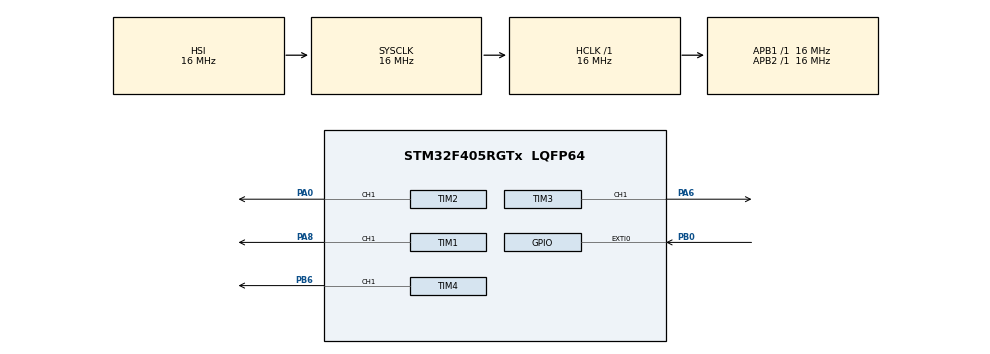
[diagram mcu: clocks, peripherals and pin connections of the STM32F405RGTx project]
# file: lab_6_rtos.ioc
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Mcu.Family=STM32F4
Mcu.Name=STM32F405RGTx
Mcu.Package=LQFP64
NVIC.EXTI0_IRQn=true\:0\:0\:false\:false\:true\:true\:true\:true
NVIC.PriorityGroup=NVIC_PRIORITYGROUP_4
PA0-WKUP.Signal=S_TIM2_CH1_ETR
PA6.Signal=S_TIM3_CH1
PA8.Signal=S_TIM1_CH1
PB0.GPIO_PuPd=GPIO_PULLDOWN
PB0.Signal=GPXTI0
PB6.Signal=S_TIM4_CH1
ProjectManager.HeapSize=0x200
ProjectManager.StackSize=0x400
ProjectManager.TargetToolchain=STM32CubeIDE
RCC.AHBFreq_Value=16000000
RCC.APB1Freq_Value=16000000
RCC.APB2Freq_Value=16000000
RCC.CortexFreq_Value=16000000
RCC.HSE_VALUE=25000000
RCC.HSI_VALUE=16000000
RCC.LSE_VALUE=32768
RCC.SYSCLKFreq_VALUE=16000000
RCC.VCOOutputFreq_Value=192000000
SH.S_TIM1_CH1.0=TIM1_CH1,PWM Generation1 CH1
SH.S_TIM2_CH1_ETR.0=TIM2_CH1,PWM Generation1 CH1
SH.S_TIM3_CH1.0=TIM3_CH1,PWM Generation1 CH1
SH.S_TIM4_CH1.0=TIM4_CH1,PWM Generation1 CH1
TIM1.Channel-PWM\ Generation1\ CH1=TIM_CHANNEL_1
TIM1.Period=41999
TIM1.Prescaler=1
TIM1.Pulse-PWM\ Generation1\ CH1=21000
TIM2.Channel-PWM\ Generation1\ CH1=TIM_CHANNEL_1
TIM2.Period=41999
TIM2.Pulse-PWM\ Generation1\ CH1=21000
TIM3.Channel-PWM\ Generation1\ CH1=TIM_CHANNEL_1
TIM3.Period=55999
TIM3.Prescaler=2
TIM3.Pulse-PWM\ Generation1\ CH1=28000
TIM4.Channel-PWM\ Generation1\ CH1=TIM_CHANNEL_1
TIM4.Period=16799
TIM4.Pulse-PWM\ Generation1\ CH1=8400
VP_TIM1_VS_ClockSourceINT.Mode=Internal
VP_TIM2_VS_ClockSourceINT.Mode=Internal
VP_TIM3_VS_ClockSourceINT.Mode=Internal
VP_TIM4_VS_ClockSourceINT.Mode=Internal
board=custom

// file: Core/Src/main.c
/* USER CODE BEGIN Header */
/**
  ******************************************************************************
  * @file           : main.c
  * @brief          : Main program body
  ******************************************************************************
  * @attention
  *
  * Copyright (c) 2026 STMicroelectronics.
  * All rights reserved.
  *
  * This software is licensed under terms that can be found in the LICENSE file
  * in the root directory of this software component.
  * If no LICENSE file comes with this software, it is provided AS-IS.
  *
  ******************************************************************************
  */
/* USER CODE END Header */
#include "main.h"

TIM_HandleTypeDef htim1;
TIM_HandleTypeDef htim2;
TIM_HandleTypeDef htim3;
TIM_HandleTypeDef htim4;

void SystemClock_Config(void);
static void MX_GPIO_Init(void);
static void MX_TIM1_Init(void);
static void MX_TIM2_Init(void);
static void MX_TIM3_Init(void);
static void MX_TIM4_Init(void);

/* USER CODE BEGIN 0 */
void HAL_GPIO_EXTI_Callback(uint16_t GPIO_Pin)
{
    if (GPIO_Pin == GPIO_PIN_0)
    {
        static uint16_t duty = 8400;

        duty += 1680;

        if (duty > 16799)
            duty = 0;

        __HAL_TIM_SET_COMPARE(&htim4, TIM_CHANNEL_1, duty);
    }
}
/* USER CODE END 0 */

int main(void)
{

  /* MCU Configuration--------------------------------------------------------*/

  /* Reset of all peripherals, Initializes the Flash interface and the Systick. */
  HAL_Init();

  /* Configure the system clock */
  SystemClock_Config();

  /* Initialize all configured peripherals */
  MX_GPIO_Init();
  MX_TIM1_Init();
  MX_TIM2_Init();
  MX_TIM3_Init();
  MX_TIM4_Init();
  /* USER CODE BEGIN 2 */
  HAL_TIM_PWM_Start(&htim1, TIM_CHANNEL_1);
  HAL_TIM_PWM_Start(&htim2, TIM_CHANNEL_1);
  HAL_TIM_PWM_Start(&htim3, TIM_CHANNEL_1);
  HAL_TIM_PWM_Start(&htim4, TIM_CHANNEL_1);
  /* USER CODE END 2 */

  /* Infinite loop */
  while (1)
  {

  }
}

void SystemClock_Config(void)
{
  RCC_OscInitTypeDef RCC_OscInitStruct = {0};
  RCC_ClkInitTypeDef RCC_ClkInitStruct = {0};

  /** Configure the main internal regulator output voltage
  */
  __HAL_RCC_PWR_CLK_ENABLE();
  __HAL_PWR_VOLTAGESCALING_CONFIG(PWR_REGULATOR_VOLTAGE_SCALE1);

  /** Initializes the RCC Oscillators according to the specified parameters
  * in the RCC_OscInitTypeDef structure.
  */
  RCC_OscInitStruct.OscillatorType = RCC_OSCILLATORTYPE_HSI;
  RCC_OscInitStruct.HSIState = RCC_HSI_ON;
  RCC_OscInitStruct.HSICalibrationValue = RCC_HSICALIBRATION_DEFAULT;
  RCC_OscInitStruct.PLL.PLLState = RCC_PLL_NONE;
  if (HAL_RCC_OscConfig(&RCC_OscInitStruct) != HAL_OK)
  {
    Error_Handler();
  }

  /** Initializes the CPU, AHB and APB buses clocks
  */
  RCC_ClkInitStruct.ClockType = RCC_CLOCKTYPE_HCLK|RCC_CLOCKTYPE_SYSCLK
                              |RCC_CLOCKTYPE_PCLK1|RCC_CLOCKTYPE_PCLK2;
  RCC_ClkInitStruct.SYSCLKSource = RCC_SYSCLKSOURCE_HSI;
  RCC_ClkInitStruct.AHBCLKDivider = RCC_SYSCLK_DIV1;
  RCC_ClkInitStruct.APB1CLKDivider = RCC_HCLK_DIV1;
  RCC_ClkInitStruct.APB2CLKDivider = RCC_HCLK_DIV1;

  if (HAL_RCC_ClockConfig(&RCC_ClkInitStruct, FLASH_LATENCY_0) != HAL_OK)
  {
    Error_Handler();
  }
}

static void MX_TIM1_Init(void)
{

  TIM_ClockConfigTypeDef sClockSourceConfig = {0};
  TIM_MasterConfigTypeDef sMasterConfig = {0};
  TIM_OC_InitTypeDef sConfigOC = {0};
  TIM_BreakDeadTimeConfigTypeDef sBreakDeadTimeConfig = {0};

  htim1.Instance = TIM1;
  htim1.Init.Prescaler = 1;
  htim1.Init.CounterMode = TIM_COUNTERMODE_UP;
  htim1.Init.Period = 41999;
  htim1.Init.ClockDivision = TIM_CLOCKDIVISION_DIV1;
  htim1.Init.RepetitionCounter = 0;
  htim1.Init.AutoReloadPreload = TIM_AUTORELOAD_PRELOAD_DISABLE;
  if (HAL_TIM_Base_Init(&htim1) != HAL_OK)
  {
    Error_Handler();
  }
  sClockSourceConfig.ClockSource = TIM_CLOCKSOURCE_INTERNAL;
  if (HAL_TIM_ConfigClockSource(&htim1, &sClockSourceConfig) != HAL_OK)
  {
    Error_Handler();
  }
  if (HAL_TIM_PWM_Init(&htim1) != HAL_OK)
  {
    Error_Handler();
  }
  sMasterConfig.MasterOutputTrigger = TIM_TRGO_RESET;
  sMasterConfig.MasterSlaveMode = TIM_MASTERSLAVEMODE_DISABLE;
  if (HAL_TIMEx_MasterConfigSynchronization(&htim1, &sMasterConfig) != HAL_OK)
  {
    Error_Handler();
  }
  sConfigOC.OCMode = TIM_OCMODE_PWM1;
  sConfigOC.Pulse = 21000;
  sConfigOC.OCPolarity = TIM_OCPOLARITY_HIGH;
  sConfigOC.OCNPolarity = TIM_OCNPOLARITY_HIGH;
  sConfigOC.OCFastMode = TIM_OCFAST_DISABLE;
  sConfigOC.OCIdleState = TIM_OCIDLESTATE_RESET;
  sConfigOC.OCNIdleState = TIM_OCNIDLESTATE_RESET;
  if (HAL_TIM_PWM_ConfigChannel(&htim1, &sConfigOC, TIM_CHANNEL_1) != HAL_OK)
  {
    Error_Handler();
  }
  sBreakDeadTimeConfig.OffStateRunMode = TIM_OSSR_DISABLE;
  sBreakDeadTimeConfig.OffStateIDLEMode = TIM_OSSI_DISABLE;
  sBreakDeadTimeConfig.LockLevel = TIM_LOCKLEVEL_OFF;
  sBreakDeadTimeConfig.DeadTime = 0;
  sBreakDeadTimeConfig.BreakState = TIM_BREAK_DISABLE;
  sBreakDeadTimeConfig.BreakPolarity = TIM_BREAKPOLARITY_HIGH;
  sBreakDeadTimeConfig.AutomaticOutput = TIM_AUTOMATICOUTPUT_DISABLE;
  if (HAL_TIMEx_ConfigBreakDeadTime(&htim1, &sBreakDeadTimeConfig) != HAL_OK)
  {
    Error_Handler();
  }
  HAL_TIM_MspPostInit(&htim1);

}

static void MX_TIM2_Init(void)
{

  TIM_ClockConfigTypeDef sClockSourceConfig = {0};
  TIM_MasterConfigTypeDef sMasterConfig = {0};
  TIM_OC_InitTypeDef sConfigOC = {0};

  htim2.Instance = TIM2;
  htim2.Init.Prescaler = 0;
  htim2.Init.CounterMode = TIM_COUNTERMODE_UP;
  htim2.Init.Period = 41999;
  htim2.Init.ClockDivision = TIM_CLOCKDIVISION_DIV1;
  htim2.Init.AutoReloadPreload = TIM_AUTORELOAD_PRELOAD_DISABLE;
  if (HAL_TIM_Base_Init(&htim2) != HAL_OK)
  {
    Error_Handler();
  }
  sClockSourceConfig.ClockSource = TIM_CLOCKSOURCE_INTERNAL;
  if (HAL_TIM_ConfigClockSource(&htim2, &sClockSourceConfig) != HAL_OK)
  {
    Error_Handler();
  }
  if (HAL_TIM_PWM_Init(&htim2) != HAL_OK)
  {
    Error_Handler();
  }
  sMasterConfig.MasterOutputTrigger = TIM_TRGO_RESET;
  sMasterConfig.MasterSlaveMode = TIM_MASTERSLAVEMODE_DISABLE;
  if (HAL_TIMEx_MasterConfigSynchronization(&htim2, &sMasterConfig) != HAL_OK)
  {
    Error_Handler();
  }
  sConfigOC.OCMode = TIM_OCMODE_PWM1;
  sConfigOC.Pulse = 21000;
  sConfigOC.OCPolarity = TIM_OCPOLARITY_HIGH;
  sConfigOC.OCFastMode = TIM_OCFAST_DISABLE;
  if (HAL_TIM_PWM_ConfigChannel(&htim2, &sConfigOC, TIM_CHANNEL_1) != HAL_OK)
  {
    Error_Handler();
  }
  HAL_TIM_MspPostInit(&htim2);

}

static void MX_TIM3_Init(void)
{

  TIM_ClockConfigTypeDef sClockSourceConfig = {0};
  TIM_MasterConfigTypeDef sMasterConfig = {0};
  TIM_OC_InitTypeDef sConfigOC = {0};

  htim3.Instance = TIM3;
  htim3.Init.Prescaler = 2;
  htim3.Init.CounterMode = TIM_COUNTERMODE_UP;
  htim3.Init.Period = 55999;
  htim3.Init.ClockDivision = TIM_CLOCKDIVISION_DIV1;
  htim3.Init.AutoReloadPreload = TIM_AUTORELOAD_PRELOAD_DISABLE;
  if (HAL_TIM_Base_Init(&htim3) != HAL_OK)
  {
    Error_Handler();
  }
  sClockSourceConfig.ClockSource = TIM_CLOCKSOURCE_INTERNAL;
  if (HAL_TIM_ConfigClockSource(&htim3, &sClockSourceConfig) != HAL_OK)
  {
    Error_Handler();
  }
  if (HAL_TIM_PWM_Init(&htim3) != HAL_OK)
  {
    Error_Handler();
  }
  sMasterConfig.MasterOutputTrigger = TIM_TRGO_RESET;
  sMasterConfig.MasterSlaveMode = TIM_MASTERSLAVEMODE_DISABLE;
  if (HAL_TIMEx_MasterConfigSynchronization(&htim3, &sMasterConfig) != HAL_OK)
  {
    Error_Handler();
  }
  sConfigOC.OCMode = TIM_OCMODE_PWM1;
  sConfigOC.Pulse = 28000;
  sConfigOC.OCPolarity = TIM_OCPOLARITY_HIGH;
  sConfigOC.OCFastMode = TIM_OCFAST_DISABLE;
  if (HAL_TIM_PWM_ConfigChannel(&htim3, &sConfigOC, TIM_CHANNEL_1) != HAL_OK)
  {
    Error_Handler();
  }
  HAL_TIM_MspPostInit(&htim3);

}

static void MX_TIM4_Init(void)
{

  TIM_ClockConfigTypeDef sClockSourceConfig = {0};
  TIM_MasterConfigTypeDef sMasterConfig = {0};
  TIM_OC_InitTypeDef sConfigOC = {0};

  htim4.Instance = TIM4;
  htim4.Init.Prescaler = 0;
  htim4.Init.CounterMode = TIM_COUNTERMODE_UP;
  htim4.Init.Period = 16799;
  htim4.Init.ClockDivision = TIM_CLOCKDIVISION_DIV1;
  htim4.Init.AutoReloadPreload = TIM_AUTORELOAD_PRELOAD_DISABLE;
  if (HAL_TIM_Base_Init(&htim4) != HAL_OK)
  {
    Error_Handler();
  }
  sClockSourceConfig.ClockSource = TIM_CLOCKSOURCE_INTERNAL;
  if (HAL_TIM_ConfigClockSource(&htim4, &sClockSourceConfig) != HAL_OK)
  {
    Error_Handler();
  }
  if (HAL_TIM_PWM_Init(&htim4) != HAL_OK)
  {
    Error_Handler();
  }
  sMasterConfig.MasterOutputTrigger = TIM_TRGO_RESET;
  sMasterConfig.MasterSlaveMode = TIM_MASTERSLAVEMODE_DISABLE;
  if (HAL_TIMEx_MasterConfigSynchronization(&htim4, &sMasterConfig) != HAL_OK)
  {
    Error_Handler();
  }
  sConfigOC.OCMode = TIM_OCMODE_PWM1;
  sConfigOC.Pulse = 8400;
  sConfigOC.OCPolarity = TIM_OCPOLARITY_HIGH;
  sConfigOC.OCFastMode = TIM_OCFAST_DISABLE;
  if (HAL_TIM_PWM_ConfigChannel(&htim4, &sConfigOC, TIM_CHANNEL_1) != HAL_OK)
  {
    Error_Handler();
  }
  HAL_TIM_MspPostInit(&htim4);

}

static void MX_GPIO_Init(void)
{
  GPIO_InitTypeDef GPIO_InitStruct = {0};

  /* GPIO Ports Clock Enable */
  __HAL_RCC_GPIOA_CLK_ENABLE();
  __HAL_RCC_GPIOB_CLK_ENABLE();

  /*Configure GPIO pin : PB0 */
  GPIO_InitStruct.Pin = GPIO_PIN_0;
  GPIO_InitStruct.Mode = GPIO_MODE_IT_RISING;
  GPIO_InitStruct.Pull = GPIO_PULLDOWN;
  HAL_GPIO_Init(GPIOB, &GPIO_InitStruct);

  /* EXTI interrupt init*/
  HAL_NVIC_SetPriority(EXTI0_IRQn, 0, 0);
  HAL_NVIC_EnableIRQ(EXTI0_IRQn);

}

void Error_Handler(void)
{
  __disable_irq();
  while (1)
  {
  }
}
